# STM32L4x6_v1r1 register map
File version: 1.1
Registers are 32-bit, read-write, reset 0x0 unless marked. A register's access mark holds for its fields unless they carry their own. Offsets are from the block's base; [hi:lo] are bit positions; {n}, {i} and the like mark numbered series; 'fields as' and 'values as' point back to an identical list.

## FMC — Flexible memory controller
Base 0xA0000000
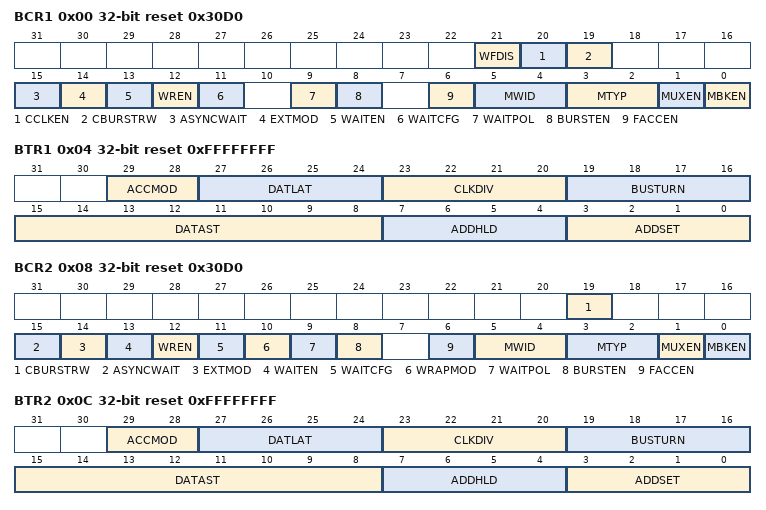
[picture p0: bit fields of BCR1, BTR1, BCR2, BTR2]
0x00 BCR1 reset 0x30D0 — SRAM/NOR-Flash chip-select control register 1
  [21] WFDIS — Write FIFO Disable
  [20] CCLKEN
  [19] CBURSTRW
  [15] ASYNCWAIT
  [14] EXTMOD
  [13] WAITEN
  [12] WREN
  [11] WAITCFG
  [9] WAITPOL
  [8] BURSTEN
  [6] FACCEN
  [5:4] MWID
  [3:2] MTYP
  [1] MUXEN
  [0] MBKEN
0x04 BTR1 reset 0xFFFFFFFF — SRAM/NOR-Flash chip-select timing register 1
  [29:28] ACCMOD, [27:24] DATLAT, [23:20] CLKDIV, [19:16] BUSTURN, [15:8] DATAST, [7:4] ADDHLD, [3:0] ADDSET
0x08 BCR2 reset 0x30D0 — SRAM/NOR-Flash chip-select control register 2
  [19] CBURSTRW, [15] ASYNCWAIT, [14] EXTMOD, [13] WAITEN, [12] WREN, [11] WAITCFG, [10] WRAPMOD, [9] WAITPOL, [8] BURSTEN, [6] FACCEN, [5:4] MWID, [3:2] MTYP, [1] MUXEN, [0] MBKEN
0x0C BTR2 reset 0xFFFFFFFF — SRAM/NOR-Flash chip-select timing register 2
  fields as BTR1
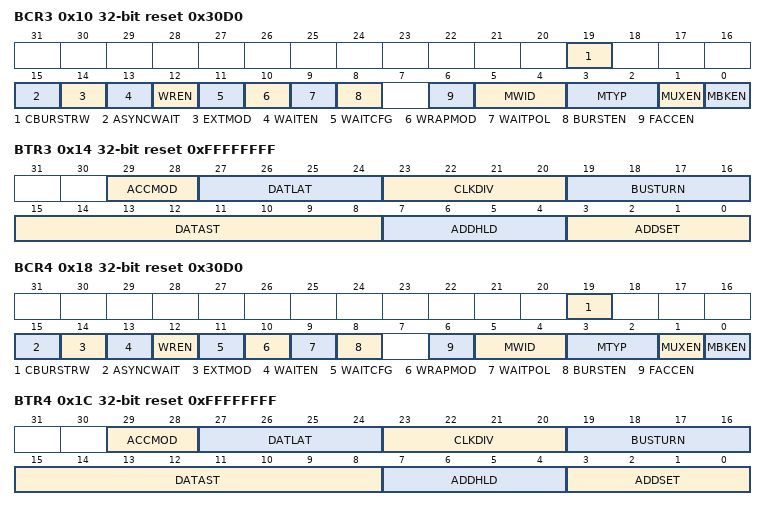
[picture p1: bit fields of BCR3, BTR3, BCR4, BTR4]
0x10 BCR3 reset 0x30D0 — SRAM/NOR-Flash chip-select control register 3
  fields as BCR2
0x14 BTR3 reset 0xFFFFFFFF — SRAM/NOR-Flash chip-select timing register 3
  fields as BTR1
0x18 BCR4 reset 0x30D0 — SRAM/NOR-Flash chip-select control register 4
  fields as BCR2
0x1C BTR4 reset 0xFFFFFFFF — SRAM/NOR-Flash chip-select timing register 4
  fields as BTR1
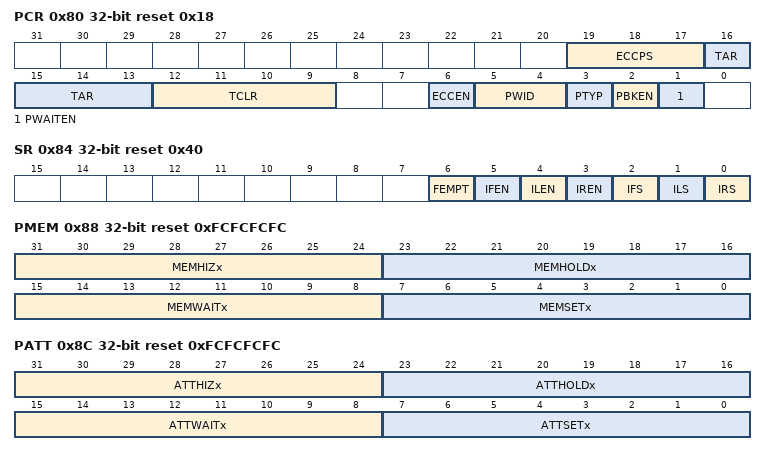
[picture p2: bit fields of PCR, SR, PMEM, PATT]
0x80 PCR reset 0x18 — PC Card/NAND Flash control register 3
  [19:17] ECCPS, [16:13] TAR, [12:9] TCLR, [6] ECCEN, [5:4] PWID, [3] PTYP, [2] PBKEN, [1] PWAITEN
0x84 SR access per field reset 0x40 — FIFO status and interrupt register 3
  [6] FEMPT ro, [5] IFEN rw, [4] ILEN rw, [3] IREN rw, [2] IFS rw, [1] ILS rw, [0] IRS rw
0x88 PMEM reset 0xFCFCFCFC — Common memory space timing register 3
  [31:24] MEMHIZx, [23:16] MEMHOLDx, [15:8] MEMWAITx, [7:0] MEMSETx
0x8C PATT reset 0xFCFCFCFC — Attribute memory space timing register 3
  [31:24] ATTHIZx, [23:16] ATTHOLDx, [15:8] ATTWAITx, [7:0] ATTSETx
0x94 ECCR ro — ECC result register 3
  [31:0] ECCx
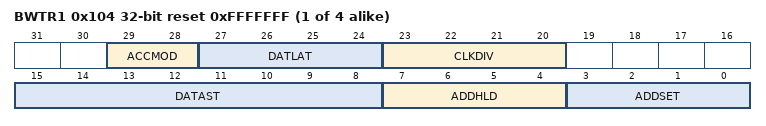
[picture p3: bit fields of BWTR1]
{0xFC+8i} BWTR{i} reset 0xFFFFFFF (i=1..4) — SRAM/NOR-Flash write timing registers {i}
  [29:28] ACCMOD, [27:24] DATLAT, [23:20] CLKDIV, [15:8] DATAST, [7:4] ADDHLD, [3:0] ADDSET

## NVIC — Nested Vectored Interrupt Controller
Base 0xE000E000
0x04 ICTR ro — Interrupt Controller Type Register
  [3:0] INTLINESNUM — Total number of interrupt lines in groups
{0x100+4i} ISER{i} (i=0..2) — Interrupt Set-Enable Register
  [31:0] SETENA
{0x180+4i} ICER{i} (i=0..2) — Interrupt Clear-Enable Register
  [31:0] CLRENA
{0x200+4i} ISPR{i} (i=0..2) — Interrupt Set-Pending Register
  [31:0] SETPEND
{0x280+4i} ICPR{i} (i=0..2) — Interrupt Clear-Pending Register
  [31:0] CLRPEND
{0x300+4i} IABR{i} ro (i=0..2) — Interrupt Active Bit Register
  [31:0] ACTIVE
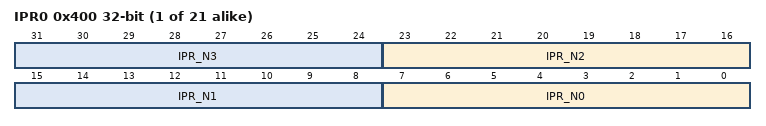
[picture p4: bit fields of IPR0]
{0x400+4i} IPR{i} (i=0..20) — Interrupt Priority Register
  [8n+7:8n] IPR_N{n} (n=0..3)
0xF00 STIR wo — Software Triggered Interrupt Register
  [8:0] INTID — interrupt to be triggered

## CRS — Clock recovery system
Base 0x40006000
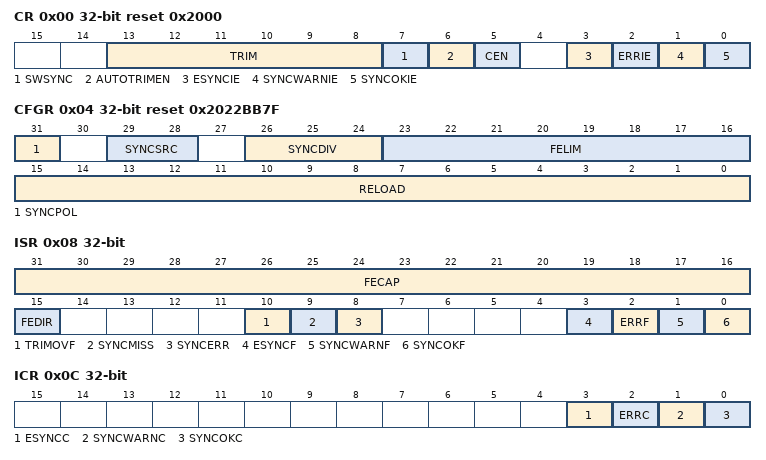
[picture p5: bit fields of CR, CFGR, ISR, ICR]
0x00 CR reset 0x2000 — control register
  [13:8] TRIM — HSI48 oscillator smooth trimming
  [7] SWSYNC — Generate software SYNC event
  [6] AUTOTRIMEN — Automatic trimming enable
  [5] CEN — Frequency error counter enable
  [3] ESYNCIE — Expected SYNC interrupt enable
  [2] ERRIE — Synchronization or trimming error interrupt enable
  [1] SYNCWARNIE — SYNC warning interrupt enable
  [0] SYNCOKIE — SYNC event OK interrupt enable
0x04 CFGR reset 0x2022BB7F — configuration register
  [31] SYNCPOL — SYNC polarity selection
  [29:28] SYNCSRC — SYNC signal source selection
  [26:24] SYNCDIV — SYNC divider
  [23:16] FELIM — Frequency error limit
  [15:0] RELOAD — Counter reload value
0x08 ISR ro — interrupt and status register
  [31:16] FECAP — Frequency error capture
  [15] FEDIR — Frequency error direction
  [10] TRIMOVF — Trimming overflow or underflow
  [9] SYNCMISS — SYNC missed
  [8] SYNCERR — SYNC error
  [3] ESYNCF — Expected SYNC flag
  [2] ERRF — Error flag
  [1] SYNCWARNF — SYNC warning flag
  [0] SYNCOKF — SYNC event OK flag
0x0C ICR — interrupt flag clear register
  [3] ESYNCC — Expected SYNC clear flag
  [2] ERRC — Error clear flag
  [1] SYNCWARNC — SYNC warning clear flag
  [0] SYNCOKC — SYNC event OK clear flag
